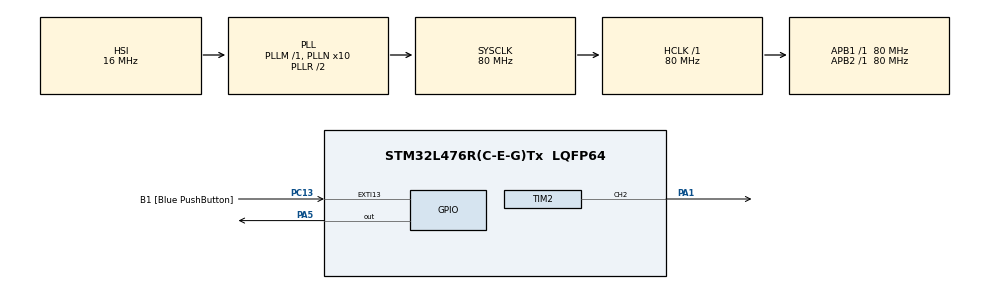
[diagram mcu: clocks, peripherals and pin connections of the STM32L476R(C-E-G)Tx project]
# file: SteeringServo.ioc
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Mcu.Family=STM32L4
Mcu.Name=STM32L476R(C-E-G)Tx
Mcu.Package=LQFP64
NVIC.PriorityGroup=NVIC_PRIORITYGROUP_4
PA1.Signal=S_TIM2_CH2
PA13\ (JTMS-SWDIO).GPIO_Label=TMS
PA13\ (JTMS-SWDIO).Signal=SYS_JTMS-SWDIO
PA14\ (JTCK-SWCLK).GPIO_Label=TCK
PA14\ (JTCK-SWCLK).Signal=SYS_JTCK-SWCLK
PA2.GPIO_Label=USART_TX
PA2.GPIO_Mode=GPIO_MODE_AF_PP
PA2.GPIO_PuPd=GPIO_NOPULL
PA2.GPIO_Speed=GPIO_SPEED_FREQ_VERY_HIGH
PA2.Signal=USART2_TX
PA3.GPIO_Label=USART_RX
PA3.GPIO_Mode=GPIO_MODE_AF_PP
PA3.GPIO_PuPd=GPIO_NOPULL
PA3.GPIO_Speed=GPIO_SPEED_FREQ_VERY_HIGH
PA3.Signal=USART2_RX
PA5.Signal=GPIO_Output
PB3\ (JTDO-TRACESWO).GPIO_Label=SWO
PB3\ (JTDO-TRACESWO).Signal=SYS_JTDO-SWO
PC13.GPIO_Label=B1 [Blue PushButton]
PC13.GPIO_ModeDefaultEXTI=GPIO_MODE_IT_FALLING
PC13.GPIO_PuPd=GPIO_NOPULL
PC13.Signal=GPXTI13
PC14-OSC32_IN\ (PC14).Signal=RCC_OSC32_IN
PC15-OSC32_OUT\ (PC15).Signal=RCC_OSC32_OUT
PH0-OSC_IN\ (PH0).Signal=RCC_OSC_IN
PH1-OSC_OUT\ (PH1).Signal=RCC_OSC_OUT
ProjectManager.HeapSize=0x200
ProjectManager.StackSize=0x400
ProjectManager.TargetToolchain=STM32CubeIDE
RCC.ADCFreq_Value=64000000
RCC.AHBFreq_Value=80000000
RCC.APB1Freq_Value=80000000
RCC.APB1TimFreq_Value=80000000
RCC.APB2Freq_Value=80000000
RCC.APB2TimFreq_Value=80000000
RCC.CortexFreq_Value=80000000
RCC.HCLKFreq_Value=80000000
RCC.HSE_VALUE=8000000
RCC.HSI_VALUE=16000000
RCC.LSE_VALUE=32768
RCC.MSI_VALUE=4000000
RCC.PLLN=10
RCC.PLLSourceVirtual=RCC_PLLSOURCE_HSI
RCC.PREFETCH_ENABLE=1
RCC.SYSCLKFreq_VALUE=80000000
RCC.SYSCLKSource=RCC_SYSCLKSOURCE_PLLCLK
RCC.USBFreq_Value=64000000
RCC.VCOOutputFreq_Value=160000000
SH.S_TIM2_CH2.0=TIM2_CH2,PWM Generation2 CH2
TIM2.AutoReloadPreload=TIM_AUTORELOAD_PRELOAD_ENABLE
TIM2.Channel-PWM\ Generation2\ CH2=TIM_CHANNEL_2
TIM2.Period=2000
TIM2.Prescaler=800-1
TIM2.Pulse-PWM\ Generation2\ CH2=1000
VP_TIM2_VS_ClockSourceINT.Mode=Internal
board=NUCLEO-L476RG

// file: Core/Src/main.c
/* USER CODE BEGIN Header */
/**
  ******************************************************************************
  * @file           : main.c
  * @brief          : Main program body
  ******************************************************************************
  * @attention
  *
  * Copyright (c) 2026 STMicroelectronics.
  * All rights reserved.
  *
  * This software is licensed under terms that can be found in the LICENSE file
  * in the root directory of this software component.
  * If no LICENSE file comes with this software, it is provided AS-IS.
  *
  ******************************************************************************
  */
/* USER CODE END Header */
#include "main.h"

TIM_HandleTypeDef htim2;

void SystemClock_Config(void);
static void MX_GPIO_Init(void);
static void MX_TIM2_Init(void);

int main(void)
{

  /* USER CODE BEGIN 1 */
	uint16_t pulseWidth = 150;  // Center position
  /* USER CODE END 1 */

  /* MCU Configuration--------------------------------------------------------*/

  /* Reset of all peripherals, Initializes the Flash interface and the Systick. */
  HAL_Init();

  /* Configure the system clock */
  SystemClock_Config();

  /* Initialize all configured peripherals */
  MX_GPIO_Init();
  MX_TIM2_Init();
  /* USER CODE BEGIN 2 */
  HAL_TIM_PWM_Start(&htim2, TIM_CHANNEL_2);
  /* USER CODE END 2 */

  /* Infinite loop */
  /* USER CODE BEGIN WHILE */
  while (1)
  {
	  if (pulseWidth < 225) {  // Until the left most position is reach, turn left slowly
	  		  __HAL_TIM_SetCompare(&htim2, TIM_CHANNEL_2, pulseWidth++);
	  	  } else {
	  		  pulseWidth = 75; // Return all the way to the right
	  	  }
	  HAL_Delay(10);  // Wait .1 second
    /* USER CODE END WHILE */

  }
}

void SystemClock_Config(void)
{
  RCC_OscInitTypeDef RCC_OscInitStruct = {0};
  RCC_ClkInitTypeDef RCC_ClkInitStruct = {0};

  /** Configure the main internal regulator output voltage
  */
  if (HAL_PWREx_ControlVoltageScaling(PWR_REGULATOR_VOLTAGE_SCALE1) != HAL_OK)
  {
    Error_Handler();
  }

  /** Initializes the RCC Oscillators according to the specified parameters
  * in the RCC_OscInitTypeDef structure.
  */
  RCC_OscInitStruct.OscillatorType = RCC_OSCILLATORTYPE_HSI;
  RCC_OscInitStruct.HSIState = RCC_HSI_ON;
  RCC_OscInitStruct.HSICalibrationValue = RCC_HSICALIBRATION_DEFAULT;
  RCC_OscInitStruct.PLL.PLLState = RCC_PLL_ON;
  RCC_OscInitStruct.PLL.PLLSource = RCC_PLLSOURCE_HSI;
  RCC_OscInitStruct.PLL.PLLM = 1;
  RCC_OscInitStruct.PLL.PLLN = 10;
  RCC_OscInitStruct.PLL.PLLP = RCC_PLLP_DIV7;
  RCC_OscInitStruct.PLL.PLLQ = RCC_PLLQ_DIV2;
  RCC_OscInitStruct.PLL.PLLR = RCC_PLLR_DIV2;
  if (HAL_RCC_OscConfig(&RCC_OscInitStruct) != HAL_OK)
  {
    Error_Handler();
  }

  /** Initializes the CPU, AHB and APB buses clocks
  */
  RCC_ClkInitStruct.ClockType = RCC_CLOCKTYPE_HCLK|RCC_CLOCKTYPE_SYSCLK
                              |RCC_CLOCKTYPE_PCLK1|RCC_CLOCKTYPE_PCLK2;
  RCC_ClkInitStruct.SYSCLKSource = RCC_SYSCLKSOURCE_PLLCLK;
  RCC_ClkInitStruct.AHBCLKDivider = RCC_SYSCLK_DIV1;
  RCC_ClkInitStruct.APB1CLKDivider = RCC_HCLK_DIV1;
  RCC_ClkInitStruct.APB2CLKDivider = RCC_HCLK_DIV1;

  if (HAL_RCC_ClockConfig(&RCC_ClkInitStruct, FLASH_LATENCY_4) != HAL_OK)
  {
    Error_Handler();
  }
}

static void MX_TIM2_Init(void)
{

  TIM_ClockConfigTypeDef sClockSourceConfig = {0};
  TIM_MasterConfigTypeDef sMasterConfig = {0};
  TIM_OC_InitTypeDef sConfigOC = {0};

  htim2.Instance = TIM2;
  htim2.Init.Prescaler = 800-1;
  htim2.Init.CounterMode = TIM_COUNTERMODE_UP;
  htim2.Init.Period = 2000;
  htim2.Init.ClockDivision = TIM_CLOCKDIVISION_DIV1;
  htim2.Init.AutoReloadPreload = TIM_AUTORELOAD_PRELOAD_ENABLE;
  if (HAL_TIM_Base_Init(&htim2) != HAL_OK)
  {
    Error_Handler();
  }
  sClockSourceConfig.ClockSource = TIM_CLOCKSOURCE_INTERNAL;
  if (HAL_TIM_ConfigClockSource(&htim2, &sClockSourceConfig) != HAL_OK)
  {
    Error_Handler();
  }
  if (HAL_TIM_PWM_Init(&htim2) != HAL_OK)
  {
    Error_Handler();
  }
  sMasterConfig.MasterOutputTrigger = TIM_TRGO_RESET;
  sMasterConfig.MasterSlaveMode = TIM_MASTERSLAVEMODE_DISABLE;
  if (HAL_TIMEx_MasterConfigSynchronization(&htim2, &sMasterConfig) != HAL_OK)
  {
    Error_Handler();
  }
  sConfigOC.OCMode = TIM_OCMODE_PWM1;
  sConfigOC.Pulse = 1000;
  sConfigOC.OCPolarity = TIM_OCPOLARITY_HIGH;
  sConfigOC.OCFastMode = TIM_OCFAST_DISABLE;
  if (HAL_TIM_PWM_ConfigChannel(&htim2, &sConfigOC, TIM_CHANNEL_2) != HAL_OK)
  {
    Error_Handler();
  }
  HAL_TIM_MspPostInit(&htim2);

}

static void MX_GPIO_Init(void)
{
  GPIO_InitTypeDef GPIO_InitStruct = {0};

  /* GPIO Ports Clock Enable */
  __HAL_RCC_GPIOC_CLK_ENABLE();
  __HAL_RCC_GPIOH_CLK_ENABLE();
  __HAL_RCC_GPIOA_CLK_ENABLE();
  __HAL_RCC_GPIOB_CLK_ENABLE();

  /*Configure GPIO pin Output Level */
  HAL_GPIO_WritePin(GPIOA, GPIO_PIN_5, GPIO_PIN_RESET);

  /*Configure GPIO pin : B1_Pin */
  GPIO_InitStruct.Pin = B1_Pin;
  GPIO_InitStruct.Mode = GPIO_MODE_IT_FALLING;
  GPIO_InitStruct.Pull = GPIO_NOPULL;
  HAL_GPIO_Init(B1_GPIO_Port, &GPIO_InitStruct);

  /*Configure GPIO pins : USART_TX_Pin USART_RX_Pin */
  GPIO_InitStruct.Pin = USART_TX_Pin|USART_RX_Pin;
  GPIO_InitStruct.Mode = GPIO_MODE_AF_PP;
  GPIO_InitStruct.Pull = GPIO_NOPULL;
  GPIO_InitStruct.Speed = GPIO_SPEED_FREQ_VERY_HIGH;
  GPIO_InitStruct.Alternate = GPIO_AF7_USART2;
  HAL_GPIO_Init(GPIOA, &GPIO_InitStruct);

  /*Configure GPIO pin : PA5 */
  GPIO_InitStruct.Pin = GPIO_PIN_5;
  GPIO_InitStruct.Mode = GPIO_MODE_OUTPUT_PP;
  GPIO_InitStruct.Pull = GPIO_NOPULL;
  GPIO_InitStruct.Speed = GPIO_SPEED_FREQ_LOW;
  HAL_GPIO_Init(GPIOA, &GPIO_InitStruct);

}

void Error_Handler(void)
{
  __disable_irq();
  while (1)
  {
  }
}
